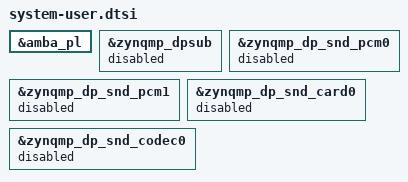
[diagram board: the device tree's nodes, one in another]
/include/ "system-conf.dtsi"

/* Remove all PL definitions, for use with FPGA-MANAGER */
&amba_pl {
  /delete-node/ axi_apio_0;
  /delete-node/ axi_apio_1;
  /delete-node/ axi_gpio_2;
  /delete-node/ axi_intc_0;
  /delete-node/ zyxclmm_drm;
};

&zynqmp_dpsub {
	status = "disabled";		
};
&zynqmp_dp_snd_pcm0 {
	status = "disabled";		
};
&zynqmp_dp_snd_pcm1 {
	status = "disabled";		
};
&zynqmp_dp_snd_card0 {
	status = "disabled";		
};
&zynqmp_dp_snd_codec0 {
	status = "disabled";		
};

